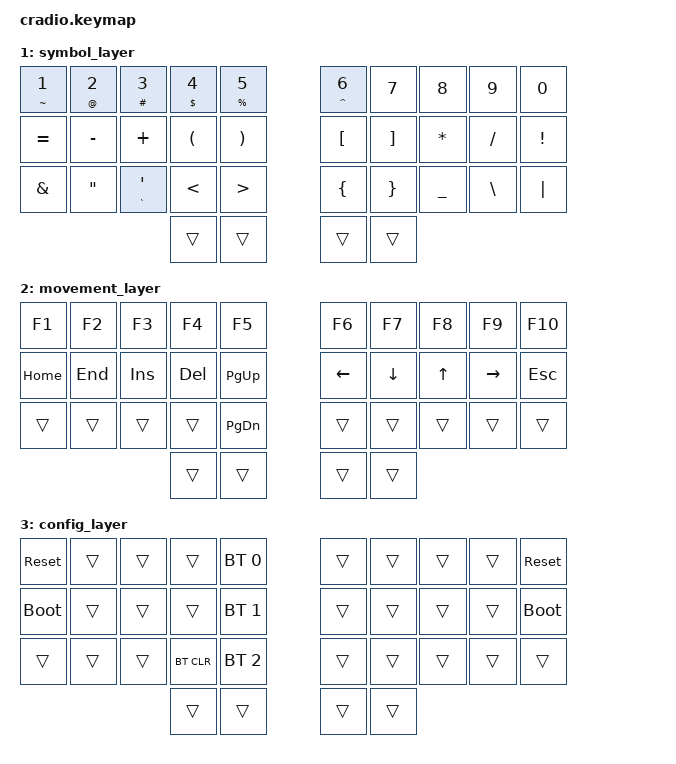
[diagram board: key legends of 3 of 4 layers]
// Copyright (c) 2022 The ZMK Contributors
// SPDX-License-Identifier: MIT

#include <behaviors.dtsi>
#include <dt-bindings/zmk/keys.h>
#include <dt-bindings/zmk/bt.h>

#define DEFAULT 0
#define SYMBOLS 1
#define MOVEMENT 2
#define CONFIG 3

// Home row mods macro
#define HRML(k1,k2,k3,k4) &ht LSHFT k1  &ht LALT k2  &ht LCTRL k3  &ht LGUI k4
#define HRMR(k1,k2,k3,k4) &ht RGUI k1  &ht RCTRL k2  &ht RALT k3  &ht RSHFT k4

/ {
    behaviors {
        ht: hold_tap {
            label = "hold_tap";
            compatible = "zmk,behavior-hold-tap";
            #binding-cells = <2>;
            flavor = "tap-preferred";
            tapping-term-ms = <200>;
            quick-tap-ms = <150>;
            global-quick-tap;
            bindings = <&kp>, <&kp>;
        };
        ld0: layer_dance_0 {
            label = "layer_dance_0";
            compatible = "zmk,behavior-tap-dance";
            tapping-term-ms = <220>;
            bindings = <&mo SYMBOLS>, <&mo MOVEMENT>, <&mo CONFIG>;
            #binding-cells = <0>;
        };
    };

    keymap {
        compatible = "zmk,keymap";
        default_layer {
            bindings = <
        //╭──────────┬──────────┬──────────┬──────────┬──────────╮   ╭──────────┬──────────┬──────────┬──────────┬──────────╮
        //│  Q       │  W       │  E       │  R       │  T       │   │  Y       │  U       │  I       │  O       │  P       │
            &kp Q      &kp W      &kp E      &kp R      &kp T          &kp Y      &kp U      &kp I      &kp O      &kp P
        //├──────────┼──────────┼──────────┼──────────┼──────────┤   ├──────────┼──────────┼──────────┼──────────┼──────────┤
        //│  A       │  S       │  D       │  F       │  G       │   │  H       │  J       │  K       │  L       │  ;       │
            HRML(A,        S,         D,         F)     &kp G          &kp H      HRMR(J,        K,         L,        SEMI)
        //├──────────┼──────────┼──────────┼──────────┼──────────┤   ├──────────┼──────────┼──────────┼──────────┼──────────┤
        //│  Z       │  X       │  C       │  V       │  B       │   │  N       │  M       │  ,       │  .       │  /       │
            &kp Z      &kp X      &kp C      &kp V      &kp B          &kp N      &kp M      &kp COMMA  &kp DOT    &kp FSLH
        //╰──────────┴──────────┴──────────┼──────────┼──────────┤   ├──────────┼──────────┼──────────┴──────────┴──────────╯
                                             &kp BSPC   &kp SPACE      &ht TAB ENTER &ld0        
        //                                 ╰──────────┴──────────╯   ╰──────────┴──────────╯
            >;
        };

        symbol_layer {
            bindings = <
        //╭──────────┬──────────┬──────────┬──────────┬──────────╮   ╭──────────┬──────────┬──────────┬──────────┬──────────╮
        //│  1       │  2       │  3       │  4       │  5       │   │  6       │  7       │  8       │  9       │  0       │
            &ht TILDE N1 &ht AT N2 &ht HASH N3 &ht DLLR N4 &ht PRCNT N5 &ht CARET N6 &kp N7   &kp N8     &kp N9     &kp N0
        //├──────────┼──────────┼──────────┼──────────┼──────────┤   ├──────────┼──────────┼──────────┼──────────┼──────────┤
        //│  =       │  -       │  +       │  (       │  )       │   │  [       │  ]       │  *       │  /       │  !       │
            &kp EQUAL  &kp MINUS  &kp PLUS   &kp LPAR   &kp RPAR       &kp LBKT   &kp RBKT   &kp ASTRK  &kp FSLH   &kp EXCL
        //├──────────┼──────────┼──────────┼──────────┼──────────┤   ├──────────┼──────────┼──────────┼──────────┼──────────┤
        //│  &       │  "       │   '      │  <       │  >       │   │  {       │  }       │  _       │  \       │  |       │
            &kp AMPS   &kp DQT     &ht GRAVE SQT &kp LT &kp GT         &kp LBRC   &kp RBRC   &kp UNDER  &kp BSLH     &kp PIPE
        //╰──────────┴──────────┴──────────┼──────────┼──────────┤   ├──────────┼──────────┼──────────┴──────────┴──────────╯
                                             &trans     &trans         &trans     &trans
        //                                 ╰──────────┴──────────╯   ╰──────────┴──────────╯
            >;
        };

        movement_layer {
            bindings = <
        //╭──────────┬──────────┬──────────┬──────────┬──────────╮   ╭──────────┬──────────┬──────────┬──────────┬──────────╮
        //│  F1      │  F2      │  F3      │  F4      │  F5      │   │  F6      │  F7      │  F8      │  F9      │  F10     │
            &kp F1     &kp F2     &kp F3     &kp F4     &kp F5         &kp F6     &kp F7     &kp F8     &kp F9     &kp F10
        //├──────────┼──────────┼──────────┼──────────┼──────────┤   ├──────────┼──────────┼──────────┼──────────┼──────────┤
        //│  HOME    │  END     │  INS     │  DEL     │  PGUP    │   │  LEFT    │  DOWN    │  UP      │  RIGHT   │  ESC     │
            &kp HOME   &kp END    &kp INS    &kp DEL    &kp PG_UP      &kp LEFT   &kp DOWN   &kp UP     &kp RIGHT  &kp ESC
        //├──────────┼──────────┼──────────┼──────────┼──────────┤   ├──────────┼──────────┼──────────┼──────────┼──────────┤
        //│          │          │          │          │  PGDN    │   │          │          │          │          │          │
            &trans     &trans     &trans     &trans     &kp PG_DN      &trans     &trans     &trans     &trans     &trans
        //╰──────────┴──────────┴──────────┼──────────┼──────────┤   ├──────────┼──────────┼──────────┴──────────┴──────────╯
                                             &trans     &trans         &trans     &trans
        //                                 ╰──────────┴──────────╯   ╰──────────┴──────────╯
            >;
        };

        config_layer {
            bindings = <
        //╭──────────┬──────────┬──────────┬──────────┬──────────╮   ╭──────────┬──────────┬──────────┬──────────┬──────────╮
        //│ RESET    │          │          │          │PROFILE 0 │   │          │          │          │          │  RESET   │
            &sys_reset &trans     &trans     &trans    &bt BT_SEL 0    &trans     &trans     &trans     &trans     &sys_reset
        //├──────────┼──────────┼──────────┼──────────┼──────────┤   ├──────────┼──────────┼──────────┼──────────┼──────────┤
        //│BOOTLOADER│          │          │          │PROFILE 1 │   │          │          │          │          │BOOTLOADER│
          &bootloader  &trans     &trans     &trans    &bt BT_SEL 1    &trans     &trans     &trans     &trans    &bootloader
        //├──────────┼──────────┼──────────┼──────────┼──────────┤   ├──────────┼──────────┼──────────┼──────────┼──────────┤
        //│          │          │          │ CLEAR BT │PROFILE 2 │   │          │          │          │          │          │
            &trans     &trans     &trans    &bt BT_CLR &bt BT_SEL 2    &trans     &trans     &trans     &trans     &trans
        //╰──────────┴──────────┴──────────┼──────────┼──────────┤   ├──────────┼──────────┼──────────┴──────────┴──────────╯
                                             &trans     &trans         &trans     &trans
        //                                 ╰──────────┴──────────╯   ╰──────────┴──────────╯
            >;
        };
    };
};
